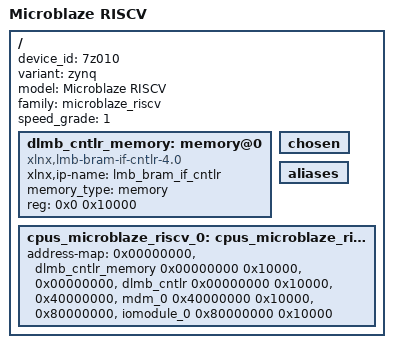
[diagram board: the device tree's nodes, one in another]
/dts-v1/;
#include "pl.dtsi"
/ {
	device_id = "7z010";
	#address-cells = <1>;
	variant = "zynq";
	model = "Microblaze RISCV";
	#size-cells = <1>;
	family = "microblaze_riscv";
	speed_grade = "1";
	dlmb_cntlr_memory: memory@0 {
		compatible = "xlnx,lmb-bram-if-cntlr-4.0";
		xlnx,ip-name = "lmb_bram_if_cntlr";
		device_type = "memory";
		memory_type = "memory";
		reg = <0x0 0x10000>;
	};
	chosen {
	};
	aliases {
	};
	cpus_microblaze_riscv_0: cpus_microblaze_riscv@0 {
		address-map = <0x00000000 &dlmb_cntlr_memory 0x00000000 0x10000>, 
			      <0x00000000 &dlmb_cntlr 0x00000000 0x10000>, 
			      <0x40000000 &mdm_0 0x40000000 0x10000>, 
			      <0x80000000 &iomodule_0 0x80000000 0x10000>;
		#ranges-address-cells = <0x1>;
		#ranges-size-cells = <0x1>;
	};
};
